# ATA8215 device description
Architecture: AVR8; Family: megaAVR
Programming and debug interfaces: ISP, debugWIRE
Registers are 8-bit, access not given, no defined reset value unless marked. A register's access mark holds for its fields unless they carry their own. Offsets are from the block's base; lines under a group give offsets from that group; [hi:lo] are bit positions; {n}, {i} and the like mark numbered series; 'fields as' and 'values as' point back to an identical list; <NAME> marks a mode.

## Ordering variants
standard: 1.9 to 3.6 V

## Memory
prog space: start 0x0000 size 0xd000, little endian
  0x0000 ROM size 0x8000 rom, ro, executable, page 0x40
signatures space: start 0 size 3, little endian
  0 SIGNATURES size 3 signatures, ro
fuses space: start 0 size 0x0001, little endian
  0 FUSES size 0x0001 fuses, rw
lockbits space: start 0 size 0x0001, little endian
  0 LOCKBITS size 0x0001 lockbits, rw
data space: start 0x0000 size 0x0600, little endian
  0x0000 REGISTERS size 0x0020 regs
  0x0020 MAPPED_IO size 0x01e0 io
  0x0200 IRAM size 0x0400 ram
eeprom space: start 0x0000 size 0x0480, little endian
  0x0000 EEPROM size 0x0400 eeprom, rw, page 0x10
  0x0400 CALDATA size 0x0080 eeprom, ro, page 0x10
io space: start 0x00 size 0x40, little endian

## Peripheral instances (address, pins/pin function, parameters)
CHFLT at 0x00
CLK at 0x00
CPU at 0x00
CRC at 0x00
DEBOUNCE at 0x00
DEBUG at 0x00
DEMOD at 0x00
DFIFO at 0x00
EEPROM at 0x00
FE at 0x00
FREQS at 0x00
FRSYNC at 0x00
GPIOREGS at 0x00
IDSCAN at 0x00
INT at 0x00
MEM at 0x00
PORTB at 0x00
PORTC at 0x00
RSSIB at 0x00
RXBUF at 0x00
RXDSP at 0x00
SFIFO at 0x00
SPI at 0x00
SSM at 0x00
SUP at 0x00
SYMCH at 0x00
TEMPER at 0x00
TIMER0_WDT at 0x00
TIMER1 at 0x00
TIMER2 at 0x00
TIMER3 at 0x00
TIMER4 at 0x00
TIMER5 at 0x00
FUSE at 0 in fuses
LOCKBIT at 0 in lockbits

## Interrupts
0 RESET — External Pin, Power-on Reset, Brown-out Reset and Watchdog Reset
1 INT0 — External Interrupt Request 0
2 INT1 — External Interrupt Request 1
3 PCI0 — Pin Change Interrupt Request 0
4 PCI1 — Pin Change Interrupt Request 1
5 VMON — Voltage Monitoring Interrupt
6 AVCCR — AVCC Reset Interrupt
7 AVCCL — AVCC Low Interrupt
8 T0INT — Timer 0 Interval Interrupt
9 T1COMP — Timer/Counter1 Compare Match Interrupt
10 T1OVF — Timer/Counter1 Overflow Interrupt
11 T2COMP — Timer/Counter2 Compare Match Interrupt
12 T2OVF — Timer/Counter2 Overflow Interrupt
13 T3CAP — Timer/Counter3 Capture Event Interrupt
14 T3COMP — Timer/Counter3 Compare Match Interrupt
15 T3OVF — Timer/Counter3 Overflow Interrupt
16 T4CAP — Timer/Counter4 Capture Event Interrupt
17 T4COMP — Timer/Counter4 Compare Match Interrupt
18 T4OVF — Timer/Counter4 Overflow Interrupt
19 T5COMP — Timer/Counter5 Compare Match Interrupt
20 T5OVF — Timer/Counter5 Overflow Interrupt
21 SPI — SPI Serial Transfer Complete Interrupt
22 SRX_FIFO — SPI Rx Buffer Interrupt
23 STX_FIFO — SPI Tx Buffer Interrupt
24 SSM — Sequencer State Machine Interrupt
25 DFFLR — Data FIFO fill level reached Interrupt
26 DFOUE — Data FIFO overflow or underflow error Interrupt
27 SFFLR — RSSI/Preamble FIFO fill level reached Interrupt
28 SFOUE — RSSI/Preamble FIFO overflow or underflow error Interrupt
29 TMTCF — Tx Modulator Telegram Finish Interrupt
30 UHF_WCOB — UHF receiver wake up ok on Rx path B
31 UHF_WCOA — UHF receiver wake up ok on Rx path A
32 UHF_SOTB — UHF receiver start of telegram ok on Rx path B
33 UHF_SOTA — UHF receiver start of telegram ok on Rx path A
34 UHF_EOTB — UHF receiver end of telegram on Rx path B
35 UHF_EOTA — UHF receiver end of telegram on Rx path A
36 UHF_NBITB — UHF receiver new bit on Rx path B
37 UHF_NBITA — UHF receiver new bit on Rx path A
38 EXCM — External input Clock monitoring Interrupt
39 ERDY — EEPROM Ready Interrupt
40 SPMR — Store Program Memory Ready
41 IDFULL — IDSCAN Full Interrupt

## Properties
SIGNATURES: JTAGID=0x9564, SIGNATURE0=0x1e, SIGNATURE1=0x95, SIGNATURE2=0x64
OCD: OCD_REVISION=1, OCD_DATAREG=0x31, PROGBASE=0x0000

## FUSE
Instances: FUSE 0 in fuses
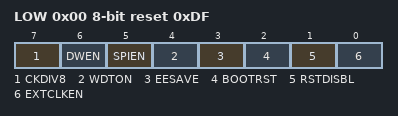
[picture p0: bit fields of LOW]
0x00 LOW reset 0xDF
  [7] CKDIV8 — Divide clock by 8 internally
  [6] DWEN — Debug Wire enable
  [5] SPIEN — Serial program downloading (SPI) enabled
  [4] WDTON — Watch-dog Timer always on
  [3] EESAVE — Preserve EEPROM memory through the Chip Erase cycle
  [2] BOOTRST — Select interrupt vector location
  [1] RSTDISBL — Disable external Reset
  [0] EXTCLKEN — External Clock enable
